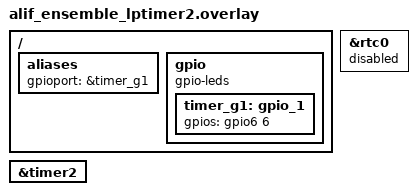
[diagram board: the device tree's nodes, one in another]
/* Copyright (c) 2024 Alif Semiconductor
 *
 * SPDX-License-Identifier: Apache-2.0
 */


/ {
	aliases {
		gpioport = &timer_g1;
	};

	gpio {
		compatible = "gpio-leds";
		timer_g1: gpio_1 {
			gpios = <&gpio6 6 0>;
		};
	};
};
/*
 * Enabling lptimer & disabling rtc for this sample application
 */

&timer2 {
	status = "okay";
};

&rtc0 {
	status = "disabled";
};
